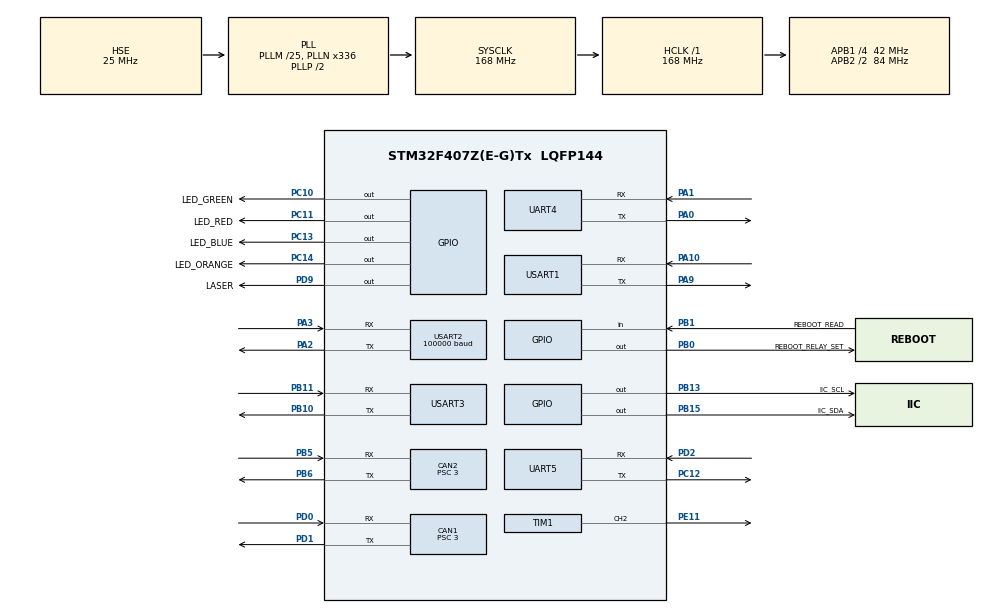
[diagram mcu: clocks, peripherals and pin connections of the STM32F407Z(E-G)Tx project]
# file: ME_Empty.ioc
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CAN1.ABOM=ENABLE
CAN1.AWUM=ENABLE
CAN1.BS1=CAN_BS1_9TQ
CAN1.BS2=CAN_BS2_4TQ
CAN1.CalculateBaudRate=1000000
CAN1.CalculateTimeBit=999.99
CAN1.CalculateTimeQuantum=71.42857142857143
CAN1.NART=ENABLE
CAN1.Prescaler=3
CAN1.TXFP=ENABLE
CAN2.ABOM=ENABLE
CAN2.AWUM=ENABLE
CAN2.BS1=CAN_BS1_9TQ
CAN2.BS2=CAN_BS2_4TQ
CAN2.CalculateBaudRate=1000000
CAN2.CalculateTimeBit=999.99
CAN2.CalculateTimeQuantum=71.42857142857143
CAN2.NART=ENABLE
CAN2.Prescaler=3
CAN2.TXFP=ENABLE
Dma.Request0=UART4_RX
Dma.Request1=UART5_RX
Dma.Request2=UART5_TX
Dma.Request3=USART1_RX
Dma.Request4=USART2_RX
Dma.Request5=USART3_RX
Dma.Request6=USART1_TX
Dma.Request7=UART4_TX
Dma.Request8=USART3_TX
Dma.UART4_RX.0.Direction=DMA_PERIPH_TO_MEMORY
Dma.UART4_RX.0.FIFOMode=DMA_FIFOMODE_DISABLE
Dma.UART4_RX.0.Instance=DMA1_Stream2
Dma.UART4_RX.0.MemDataAlignment=DMA_MDATAALIGN_BYTE
Dma.UART4_RX.0.MemInc=DMA_MINC_ENABLE
Dma.UART4_RX.0.Mode=DMA_CIRCULAR
Dma.UART4_RX.0.PeriphDataAlignment=DMA_PDATAALIGN_BYTE
Dma.UART4_RX.0.PeriphInc=DMA_PINC_DISABLE
Dma.UART4_RX.0.Priority=DMA_PRIORITY_LOW
Dma.UART4_TX.7.Direction=DMA_MEMORY_TO_PERIPH
Dma.UART4_TX.7.FIFOMode=DMA_FIFOMODE_DISABLE
Dma.UART4_TX.7.Instance=DMA1_Stream4
Dma.UART4_TX.7.MemDataAlignment=DMA_MDATAALIGN_BYTE
Dma.UART4_TX.7.MemInc=DMA_MINC_ENABLE
Dma.UART4_TX.7.Mode=DMA_NORMAL
Dma.UART4_TX.7.PeriphDataAlignment=DMA_PDATAALIGN_BYTE
Dma.UART4_TX.7.PeriphInc=DMA_PINC_DISABLE
Dma.UART4_TX.7.Priority=DMA_PRIORITY_LOW
Dma.UART5_RX.1.Direction=DMA_PERIPH_TO_MEMORY
Dma.UART5_RX.1.FIFOMode=DMA_FIFOMODE_DISABLE
Dma.UART5_RX.1.Instance=DMA1_Stream0
Dma.UART5_RX.1.MemDataAlignment=DMA_MDATAALIGN_BYTE
Dma.UART5_RX.1.MemInc=DMA_MINC_ENABLE
Dma.UART5_RX.1.Mode=DMA_CIRCULAR
Dma.UART5_RX.1.PeriphDataAlignment=DMA_PDATAALIGN_BYTE
Dma.UART5_RX.1.PeriphInc=DMA_PINC_DISABLE
Dma.UART5_RX.1.Priority=DMA_PRIORITY_LOW
Dma.UART5_TX.2.Direction=DMA_MEMORY_TO_PERIPH
Dma.UART5_TX.2.FIFOMode=DMA_FIFOMODE_DISABLE
Dma.UART5_TX.2.Instance=DMA1_Stream7
Dma.UART5_TX.2.MemDataAlignment=DMA_MDATAALIGN_BYTE
Dma.UART5_TX.2.MemInc=DMA_MINC_ENABLE
Dma.UART5_TX.2.Mode=DMA_NORMAL
Dma.UART5_TX.2.PeriphDataAlignment=DMA_PDATAALIGN_BYTE
Dma.UART5_TX.2.PeriphInc=DMA_PINC_DISABLE
Dma.UART5_TX.2.Priority=DMA_PRIORITY_LOW
Dma.USART1_RX.3.Direction=DMA_PERIPH_TO_MEMORY
Dma.USART1_RX.3.FIFOMode=DMA_FIFOMODE_DISABLE
Dma.USART1_RX.3.Instance=DMA2_Stream2
Dma.USART1_RX.3.MemDataAlignment=DMA_MDATAALIGN_BYTE
Dma.USART1_RX.3.MemInc=DMA_MINC_ENABLE
Dma.USART1_RX.3.Mode=DMA_CIRCULAR
Dma.USART1_RX.3.PeriphDataAlignment=DMA_PDATAALIGN_BYTE
Dma.USART1_RX.3.PeriphInc=DMA_PINC_DISABLE
Dma.USART1_RX.3.Priority=DMA_PRIORITY_VERY_HIGH
Dma.USART1_TX.6.Direction=DMA_MEMORY_TO_PERIPH
Dma.USART1_TX.6.FIFOMode=DMA_FIFOMODE_DISABLE
Dma.USART1_TX.6.Instance=DMA2_Stream7
Dma.USART1_TX.6.MemDataAlignment=DMA_MDATAALIGN_BYTE
Dma.USART1_TX.6.MemInc=DMA_MINC_ENABLE
Dma.USART1_TX.6.Mode=DMA_NORMAL
Dma.USART1_TX.6.PeriphDataAlignment=DMA_PDATAALIGN_BYTE
Dma.USART1_TX.6.PeriphInc=DMA_PINC_DISABLE
Dma.USART1_TX.6.Priority=DMA_PRIORITY_VERY_HIGH
Dma.USART2_RX.4.Direction=DMA_PERIPH_TO_MEMORY
Dma.USART2_RX.4.FIFOMode=DMA_FIFOMODE_DISABLE
Dma.USART2_RX.4.Instance=DMA1_Stream5
Dma.USART2_RX.4.MemDataAlignment=DMA_MDATAALIGN_BYTE
Dma.USART2_RX.4.MemInc=DMA_MINC_ENABLE
Dma.USART2_RX.4.Mode=DMA_CIRCULAR
Dma.USART2_RX.4.PeriphDataAlignment=DMA_PDATAALIGN_BYTE
Dma.USART2_RX.4.PeriphInc=DMA_PINC_DISABLE
Dma.USART2_RX.4.Priority=DMA_PRIORITY_LOW
Dma.USART3_RX.5.Direction=DMA_PERIPH_TO_MEMORY
Dma.USART3_RX.5.FIFOMode=DMA_FIFOMODE_DISABLE
Dma.USART3_RX.5.Instance=DMA1_Stream1
Dma.USART3_RX.5.MemDataAlignment=DMA_MDATAALIGN_BYTE
Dma.USART3_RX.5.MemInc=DMA_MINC_ENABLE
Dma.USART3_RX.5.Mode=DMA_CIRCULAR
Dma.USART3_RX.5.PeriphDataAlignment=DMA_PDATAALIGN_BYTE
Dma.USART3_RX.5.PeriphInc=DMA_PINC_DISABLE
Dma.USART3_RX.5.Priority=DMA_PRIORITY_HIGH
Dma.USART3_TX.8.Direction=DMA_MEMORY_TO_PERIPH
Dma.USART3_TX.8.FIFOMode=DMA_FIFOMODE_DISABLE
Dma.USART3_TX.8.Instance=DMA1_Stream3
Dma.USART3_TX.8.MemDataAlignment=DMA_MDATAALIGN_BYTE
Dma.USART3_TX.8.MemInc=DMA_MINC_ENABLE
Dma.USART3_TX.8.Mode=DMA_NORMAL
Dma.USART3_TX.8.PeriphDataAlignment=DMA_PDATAALIGN_BYTE
Dma.USART3_TX.8.PeriphInc=DMA_PINC_DISABLE
Dma.USART3_TX.8.Priority=DMA_PRIORITY_HIGH
FREERTOS.Tasks01=defaultTask,0,128,StartDefaultTask,Default,NULL,Dynamic,NULL,NULL;RealtimeTask,2,1024,Realtime_Task,As weak,NULL,Dynamic,NULL,NULL;ControlTask,1,1024,Control_Task,As weak,NULL,Dynamic,NULL,NULL;interactiontask,1,256,Interaction_Task,As weak,NULL,Dynamic,NULL,NULL
Mcu.Family=STM32F4
Mcu.Name=STM32F407Z(E-G)Tx
Mcu.Package=LQFP144
NVIC.CAN1_RX0_IRQn=true\:5\:0\:false\:false\:true\:true\:true\:true
NVIC.CAN2_RX0_IRQn=true\:5\:0\:false\:false\:true\:true\:true\:true
NVIC.DMA1_Stream0_IRQn=true\:5\:0\:false\:false\:true\:true\:false\:true
NVIC.DMA1_Stream1_IRQn=true\:5\:0\:false\:false\:true\:true\:false\:true
NVIC.DMA1_Stream2_IRQn=true\:5\:0\:false\:false\:true\:true\:false\:true
NVIC.DMA1_Stream3_IRQn=true\:5\:0\:false\:false\:true\:true\:false\:true
NVIC.DMA1_Stream4_IRQn=true\:5\:0\:false\:false\:true\:true\:false\:true
NVIC.DMA1_Stream5_IRQn=true\:5\:0\:false\:false\:true\:true\:false\:true
NVIC.DMA1_Stream7_IRQn=true\:5\:0\:false\:false\:true\:true\:false\:true
NVIC.DMA2_Stream2_IRQn=true\:5\:0\:false\:false\:true\:true\:false\:true
NVIC.DMA2_Stream7_IRQn=true\:5\:0\:false\:false\:true\:true\:false\:true
NVIC.PriorityGroup=NVIC_PRIORITYGROUP_4
NVIC.TIM2_IRQn=true\:15\:0\:false\:false\:true\:false\:false\:true
NVIC.TimeBase=TIM2_IRQn
NVIC.TimeBaseIP=TIM2
NVIC.UART4_IRQn=true\:5\:0\:false\:false\:true\:true\:true\:true
NVIC.UART5_IRQn=true\:5\:0\:false\:false\:true\:true\:true\:true
NVIC.USART1_IRQn=true\:5\:0\:false\:false\:true\:true\:true\:true
NVIC.USART2_IRQn=true\:5\:0\:false\:false\:true\:true\:true\:true
NVIC.USART3_IRQn=true\:5\:0\:false\:false\:true\:true\:true\:true
PA0-WKUP.Mode=Asynchronous
PA0-WKUP.Signal=UART4_TX
PA1.Mode=Asynchronous
PA1.Signal=UART4_RX
PA10.Mode=Asynchronous
PA10.Signal=USART1_RX
PA13.Mode=Serial_Wire
PA13.Signal=SYS_JTMS-SWDIO
PA14.Mode=Serial_Wire
PA14.Signal=SYS_JTCK-SWCLK
PA2.Mode=Asynchronous
PA2.Signal=USART2_TX
PA3.Mode=Asynchronous
PA3.Signal=USART2_RX
PA6.Signal=S_TIM3_CH1
PA7.Signal=S_TIM3_CH2
PA9.Mode=Asynchronous
PA9.Signal=USART1_TX
PB0.GPIO_Label=REBOOT_RELAY_SET
PB0.Signal=GPIO_Output
PB1.GPIO_Label=REBOOT_READ
PB1.Signal=GPIO_Input
PB10.Mode=Asynchronous
PB10.Signal=USART3_TX
PB11.Mode=Asynchronous
PB11.Signal=USART3_RX
PB13.GPIO_Label=IIC_SCL
PB13.GPIO_Speed=GPIO_SPEED_FREQ_VERY_HIGH
PB13.PinState=GPIO_PIN_SET
PB13.Signal=GPIO_Output
PB15.GPIO_Label=IIC_SDA
PB15.GPIO_Speed=GPIO_SPEED_FREQ_VERY_HIGH
PB15.PinState=GPIO_PIN_SET
PB15.Signal=GPIO_Output
PB5.Mode=CAN_Activate
PB5.Signal=CAN2_RX
PB6.Mode=CAN_Activate
PB6.Signal=CAN2_TX
PC10.GPIO_Label=LED_GREEN
PC10.Signal=GPIO_Output
PC11.GPIO_Label=LED_RED
PC11.PinState=GPIO_PIN_SET
PC11.Signal=GPIO_Output
PC12.Mode=Asynchronous
PC12.Signal=UART5_TX
PC13-ANTI_TAMP.GPIO_Label=LED_BLUE
PC13-ANTI_TAMP.PinState=GPIO_PIN_SET
PC13-ANTI_TAMP.Signal=GPIO_Output
PC14-OSC32_IN.GPIO_Label=LED_ORANGE
PC14-OSC32_IN.PinState=GPIO_PIN_SET
PC14-OSC32_IN.Signal=GPIO_Output
PC6.Signal=S_TIM8_CH1
PC7.Signal=S_TIM8_CH2
PC8.Signal=S_TIM8_CH3
PC9.Signal=S_TIM8_CH4
PD0.Mode=CAN_Activate
PD0.Signal=CAN1_RX
PD1.Mode=CAN_Activate
PD1.Signal=CAN1_TX
PD12.Signal=S_TIM4_CH1
PD13.Signal=S_TIM4_CH2
PD14.Signal=S_TIM4_CH3
PD15.Signal=S_TIM4_CH4
PD2.Mode=Asynchronous
PD2.Signal=UART5_RX
PD9.GPIO_Label=LASER
PD9.PinState=GPIO_PIN_SET
PD9.Signal=GPIO_Output
PE11.Signal=S_TIM1_CH2
PE9.Signal=S_TIM1_CH1
PH0-OSC_IN.Mode=HSE-External-Oscillator
PH0-OSC_IN.Signal=RCC_OSC_IN
PH1-OSC_OUT.Mode=HSE-External-Oscillator
PH1-OSC_OUT.Signal=RCC_OSC_OUT
ProjectManager.HeapSize=0x200
ProjectManager.StackSize=0x400
ProjectManager.TargetToolchain=MDK-ARM V5.32
RCC.48MHZClocksFreq_Value=84000000
RCC.AHBFreq_Value=168000000
RCC.APB1CLKDivider=RCC_HCLK_DIV4
RCC.APB1Freq_Value=42000000
RCC.APB1TimFreq_Value=84000000
RCC.APB2CLKDivider=RCC_HCLK_DIV2
RCC.APB2Freq_Value=84000000
RCC.APB2TimFreq_Value=168000000
RCC.CortexFreq_Value=168000000
RCC.HCLKFreq_Value=168000000
RCC.HSE_VALUE=25000000
RCC.HSI_VALUE=16000000
RCC.LSE_VALUE=32768
RCC.PLLM=25
RCC.PLLN=336
RCC.PLLSourceVirtual=RCC_PLLSOURCE_HSE
RCC.SYSCLKFreq_VALUE=168000000
RCC.SYSCLKSource=RCC_SYSCLKSOURCE_PLLCLK
RCC.VCOOutputFreq_Value=336000000
SH.S_TIM1_CH1.0=TIM1_CH1
SH.S_TIM1_CH2.0=TIM1_CH2,PWM Generation2 CH2
SH.S_TIM3_CH1.0=TIM3_CH1
SH.S_TIM3_CH2.0=TIM3_CH2
SH.S_TIM4_CH1.0=TIM4_CH1
SH.S_TIM4_CH2.0=TIM4_CH2
SH.S_TIM4_CH3.0=TIM4_CH3
SH.S_TIM4_CH4.0=TIM4_CH4
SH.S_TIM8_CH1.0=TIM8_CH1
SH.S_TIM8_CH2.0=TIM8_CH2
SH.S_TIM8_CH3.0=TIM8_CH3
SH.S_TIM8_CH4.0=TIM8_CH4
TIM1.Channel-PWM\ Generation2\ CH2=TIM_CHANNEL_2
TIM1.Period=1000-1
TIM1.Prescaler=3360-1
UART4.VirtualMode=Asynchronous
UART5.VirtualMode=Asynchronous
USART1.VirtualMode=VM_ASYNC
USART2.BaudRate=100000
USART2.Parity=PARITY_EVEN
USART2.VirtualMode=VM_ASYNC
USART3.VirtualMode=VM_ASYNC
VP_FREERTOS_VS_CMSIS_V1.Mode=CMSIS_V1
VP_SYS_VS_tim2.Mode=TIM2
board=custom

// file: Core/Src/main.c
/* USER CODE BEGIN Header */
/**
  ******************************************************************************
  * @file           : main.c
  * @brief          : Main program body
  ******************************************************************************
  * @attention
  *
  * <h2><center>&copy; Copyright (c) 2021 STMicroelectronics.
  * All rights reserved.</center></h2>
  *
  * This software component is licensed by ST under Ultimate Liberty license
  * SLA0044, the "License"; You may not use this file except in compliance with
  * the License. You may obtain a copy of the License at:
  *                             www.st.com/SLA0044
  *
  ******************************************************************************
  */
/* USER CODE END Header */
#include "main.h"
#include "cmsis_os.h"

/* USER CODE BEGIN Includes */
#include "drive.h"
#include "bmi2_defs.h"
#include "bmi.h"
/* USER CODE END Includes */

CAN_HandleTypeDef hcan1;
CAN_HandleTypeDef hcan2;

TIM_HandleTypeDef htim1;

UART_HandleTypeDef huart4;
UART_HandleTypeDef huart5;
UART_HandleTypeDef huart1;
UART_HandleTypeDef huart2;
UART_HandleTypeDef huart3;
DMA_HandleTypeDef hdma_uart4_rx;
DMA_HandleTypeDef hdma_uart4_tx;
DMA_HandleTypeDef hdma_uart5_rx;
DMA_HandleTypeDef hdma_uart5_tx;
DMA_HandleTypeDef hdma_usart1_rx;
DMA_HandleTypeDef hdma_usart1_tx;
DMA_HandleTypeDef hdma_usart2_rx;
DMA_HandleTypeDef hdma_usart3_rx;
DMA_HandleTypeDef hdma_usart3_tx;

osThreadId defaultTaskHandle;
osThreadId RealtimeTaskHandle;
osThreadId ControlTaskHandle;
osThreadId interactiontaskHandle;

void SystemClock_Config(void);
static void MX_GPIO_Init(void);
static void MX_CAN2_Init(void);
static void MX_DMA_Init(void);
static void MX_CAN1_Init(void);
static void MX_UART4_Init(void);
static void MX_UART5_Init(void);
static void MX_USART1_UART_Init(void);
static void MX_USART2_UART_Init(void);
static void MX_USART3_UART_Init(void);
static void MX_TIM1_Init(void);
void StartDefaultTask(void const * argument);
void Realtime_Task(void const * argument);
void Control_Task(void const * argument);
void Interaction_Task(void const * argument);

int main(void)
{

  /* MCU Configuration--------------------------------------------------------*/

  /* Reset of all peripherals, Initializes the Flash interface and the Systick. */
  HAL_Init();

  /* Configure the system clock */
  SystemClock_Config();

  /* USER CODE BEGIN SysInit */
//	HAL_Delay(500);
//	while(BMI_Init()!=BMI2_OK){}
  /* USER CODE END SysInit */

  /* Initialize all configured peripherals */
  MX_GPIO_Init();
  MX_CAN2_Init();
  MX_DMA_Init();
  MX_CAN1_Init();
  MX_UART4_Init();
  MX_UART5_Init();
  MX_USART1_UART_Init();
  MX_USART2_UART_Init();
  MX_USART3_UART_Init();
  MX_TIM1_Init();
  /* USER CODE BEGIN 2 */
	drive_init();
	module_init();
  /* USER CODE END 2 */

  /* Create the thread(s) */
  /* definition and creation of defaultTask */
  osThreadDef(defaultTask, StartDefaultTask, osPriorityNormal, 0, 128);
  defaultTaskHandle = osThreadCreate(osThread(defaultTask), NULL);

  /* definition and creation of RealtimeTask */
  osThreadDef(RealtimeTask, Realtime_Task, osPriorityHigh, 0, 1024);
  RealtimeTaskHandle = osThreadCreate(osThread(RealtimeTask), NULL);

  /* definition and creation of ControlTask */
  osThreadDef(ControlTask, Control_Task, osPriorityAboveNormal, 0, 1024);
  ControlTaskHandle = osThreadCreate(osThread(ControlTask), NULL);

  /* definition and creation of interactiontask */
  osThreadDef(interactiontask, Interaction_Task, osPriorityAboveNormal, 0, 256);
  interactiontaskHandle = osThreadCreate(osThread(interactiontask), NULL);

  /* Start scheduler */
  osKernelStart();

  /* We should never get here as control is now taken by the scheduler */
  /* Infinite loop */
  while (1)
  {

  }
}

void SystemClock_Config(void)
{
  RCC_OscInitTypeDef RCC_OscInitStruct = {0};
  RCC_ClkInitTypeDef RCC_ClkInitStruct = {0};

  /** Configure the main internal regulator output voltage
  */
  __HAL_RCC_PWR_CLK_ENABLE();
  __HAL_PWR_VOLTAGESCALING_CONFIG(PWR_REGULATOR_VOLTAGE_SCALE1);
  /** Initializes the RCC Oscillators according to the specified parameters
  * in the RCC_OscInitTypeDef structure.
  */
  RCC_OscInitStruct.OscillatorType = RCC_OSCILLATORTYPE_HSE;
  RCC_OscInitStruct.HSEState = RCC_HSE_ON;
  RCC_OscInitStruct.PLL.PLLState = RCC_PLL_ON;
  RCC_OscInitStruct.PLL.PLLSource = RCC_PLLSOURCE_HSE;
  RCC_OscInitStruct.PLL.PLLM = 25;
  RCC_OscInitStruct.PLL.PLLN = 336;
  RCC_OscInitStruct.PLL.PLLP = RCC_PLLP_DIV2;
  RCC_OscInitStruct.PLL.PLLQ = 4;
  if (HAL_RCC_OscConfig(&RCC_OscInitStruct) != HAL_OK)
  {
    Error_Handler();
  }
  /** Initializes the CPU, AHB and APB buses clocks
  */
  RCC_ClkInitStruct.ClockType = RCC_CLOCKTYPE_HCLK|RCC_CLOCKTYPE_SYSCLK
                              |RCC_CLOCKTYPE_PCLK1|RCC_CLOCKTYPE_PCLK2;
  RCC_ClkInitStruct.SYSCLKSource = RCC_SYSCLKSOURCE_PLLCLK;
  RCC_ClkInitStruct.AHBCLKDivider = RCC_SYSCLK_DIV1;
  RCC_ClkInitStruct.APB1CLKDivider = RCC_HCLK_DIV4;
  RCC_ClkInitStruct.APB2CLKDivider = RCC_HCLK_DIV2;

  if (HAL_RCC_ClockConfig(&RCC_ClkInitStruct, FLASH_LATENCY_5) != HAL_OK)
  {
    Error_Handler();
  }
}

static void MX_CAN1_Init(void)
{

  hcan1.Instance = CAN1;
  hcan1.Init.Prescaler = 3;
  hcan1.Init.Mode = CAN_MODE_NORMAL;
  hcan1.Init.SyncJumpWidth = CAN_SJW_1TQ;
  hcan1.Init.TimeSeg1 = CAN_BS1_9TQ;
  hcan1.Init.TimeSeg2 = CAN_BS2_4TQ;
  hcan1.Init.TimeTriggeredMode = DISABLE;
  hcan1.Init.AutoBusOff = ENABLE;
  hcan1.Init.AutoWakeUp = ENABLE;
  hcan1.Init.AutoRetransmission = ENABLE;
  hcan1.Init.ReceiveFifoLocked = DISABLE;
  hcan1.Init.TransmitFifoPriority = ENABLE;
  if (HAL_CAN_Init(&hcan1) != HAL_OK)
  {
    Error_Handler();
  }

}

static void MX_CAN2_Init(void)
{

  hcan2.Instance = CAN2;
  hcan2.Init.Prescaler = 3;
  hcan2.Init.Mode = CAN_MODE_NORMAL;
  hcan2.Init.SyncJumpWidth = CAN_SJW_1TQ;
  hcan2.Init.TimeSeg1 = CAN_BS1_9TQ;
  hcan2.Init.TimeSeg2 = CAN_BS2_4TQ;
  hcan2.Init.TimeTriggeredMode = DISABLE;
  hcan2.Init.AutoBusOff = ENABLE;
  hcan2.Init.AutoWakeUp = ENABLE;
  hcan2.Init.AutoRetransmission = ENABLE;
  hcan2.Init.ReceiveFifoLocked = DISABLE;
  hcan2.Init.TransmitFifoPriority = ENABLE;
  if (HAL_CAN_Init(&hcan2) != HAL_OK)
  {
    Error_Handler();
  }

}

static void MX_TIM1_Init(void)
{

  TIM_MasterConfigTypeDef sMasterConfig = {0};
  TIM_OC_InitTypeDef sConfigOC = {0};
  TIM_BreakDeadTimeConfigTypeDef sBreakDeadTimeConfig = {0};

  htim1.Instance = TIM1;
  htim1.Init.Prescaler = 3360-1;
  htim1.Init.CounterMode = TIM_COUNTERMODE_UP;
  htim1.Init.Period = 1000-1;
  htim1.Init.ClockDivision = TIM_CLOCKDIVISION_DIV1;
  htim1.Init.RepetitionCounter = 0;
  htim1.Init.AutoReloadPreload = TIM_AUTORELOAD_PRELOAD_DISABLE;
  if (HAL_TIM_PWM_Init(&htim1) != HAL_OK)
  {
    Error_Handler();
  }
  sMasterConfig.MasterOutputTrigger = TIM_TRGO_RESET;
  sMasterConfig.MasterSlaveMode = TIM_MASTERSLAVEMODE_DISABLE;
  if (HAL_TIMEx_MasterConfigSynchronization(&htim1, &sMasterConfig) != HAL_OK)
  {
    Error_Handler();
  }
  sConfigOC.OCMode = TIM_OCMODE_PWM1;
  sConfigOC.Pulse = 0;
  sConfigOC.OCPolarity = TIM_OCPOLARITY_HIGH;
  sConfigOC.OCNPolarity = TIM_OCNPOLARITY_HIGH;
  sConfigOC.OCFastMode = TIM_OCFAST_DISABLE;
  sConfigOC.OCIdleState = TIM_OCIDLESTATE_RESET;
  sConfigOC.OCNIdleState = TIM_OCNIDLESTATE_RESET;
  if (HAL_TIM_PWM_ConfigChannel(&htim1, &sConfigOC, TIM_CHANNEL_2) != HAL_OK)
  {
    Error_Handler();
  }
  sBreakDeadTimeConfig.OffStateRunMode = TIM_OSSR_DISABLE;
  sBreakDeadTimeConfig.OffStateIDLEMode = TIM_OSSI_DISABLE;
  sBreakDeadTimeConfig.LockLevel = TIM_LOCKLEVEL_OFF;
  sBreakDeadTimeConfig.DeadTime = 0;
  sBreakDeadTimeConfig.BreakState = TIM_BREAK_DISABLE;
  sBreakDeadTimeConfig.BreakPolarity = TIM_BREAKPOLARITY_HIGH;
  sBreakDeadTimeConfig.AutomaticOutput = TIM_AUTOMATICOUTPUT_DISABLE;
  if (HAL_TIMEx_ConfigBreakDeadTime(&htim1, &sBreakDeadTimeConfig) != HAL_OK)
  {
    Error_Handler();
  }
  HAL_TIM_MspPostInit(&htim1);

}

static void MX_UART4_Init(void)
{

  huart4.Instance = UART4;
  huart4.Init.BaudRate = 115200;
  huart4.Init.WordLength = UART_WORDLENGTH_8B;
  huart4.Init.StopBits = UART_STOPBITS_1;
  huart4.Init.Parity = UART_PARITY_NONE;
  huart4.Init.Mode = UART_MODE_TX_RX;
  huart4.Init.HwFlowCtl = UART_HWCONTROL_NONE;
  huart4.Init.OverSampling = UART_OVERSAMPLING_16;
  if (HAL_UART_Init(&huart4) != HAL_OK)
  {
    Error_Handler();
  }

}

static void MX_UART5_Init(void)
{

  huart5.Instance = UART5;
  huart5.Init.BaudRate = 115200;
  huart5.Init.WordLength = UART_WORDLENGTH_8B;
  huart5.Init.StopBits = UART_STOPBITS_1;
  huart5.Init.Parity = UART_PARITY_NONE;
  huart5.Init.Mode = UART_MODE_TX_RX;
  huart5.Init.HwFlowCtl = UART_HWCONTROL_NONE;
  huart5.Init.OverSampling = UART_OVERSAMPLING_16;
  if (HAL_UART_Init(&huart5) != HAL_OK)
  {
    Error_Handler();
  }

}

static void MX_USART1_UART_Init(void)
{

  huart1.Instance = USART1;
  huart1.Init.BaudRate = 115200;
  huart1.Init.WordLength = UART_WORDLENGTH_8B;
  huart1.Init.StopBits = UART_STOPBITS_1;
  huart1.Init.Parity = UART_PARITY_NONE;
  huart1.Init.Mode = UART_MODE_TX_RX;
  huart1.Init.HwFlowCtl = UART_HWCONTROL_NONE;
  huart1.Init.OverSampling = UART_OVERSAMPLING_16;
  if (HAL_UART_Init(&huart1) != HAL_OK)
  {
    Error_Handler();
  }

}

static void MX_USART2_UART_Init(void)
{

  huart2.Instance = USART2;
  huart2.Init.BaudRate = 100000;
  huart2.Init.WordLength = UART_WORDLENGTH_8B;
  huart2.Init.StopBits = UART_STOPBITS_1;
  huart2.Init.Parity = UART_PARITY_EVEN;
  huart2.Init.Mode = UART_MODE_TX_RX;
  huart2.Init.HwFlowCtl = UART_HWCONTROL_NONE;
  huart2.Init.OverSampling = UART_OVERSAMPLING_16;
  if (HAL_UART_Init(&huart2) != HAL_OK)
  {
    Error_Handler();
  }

}

static void MX_USART3_UART_Init(void)
{

  huart3.Instance = USART3;
  huart3.Init.BaudRate = 115200;
  huart3.Init.WordLength = UART_WORDLENGTH_8B;
  huart3.Init.StopBits = UART_STOPBITS_1;
  huart3.Init.Parity = UART_PARITY_NONE;
  huart3.Init.Mode = UART_MODE_TX_RX;
  huart3.Init.HwFlowCtl = UART_HWCONTROL_NONE;
  huart3.Init.OverSampling = UART_OVERSAMPLING_16;
  if (HAL_UART_Init(&huart3) != HAL_OK)
  {
    Error_Handler();
  }

}

static void MX_DMA_Init(void)
{

  /* DMA controller clock enable */
  __HAL_RCC_DMA1_CLK_ENABLE();
  __HAL_RCC_DMA2_CLK_ENABLE();

  /* DMA interrupt init */
  /* DMA1_Stream0_IRQn interrupt configuration */
  HAL_NVIC_SetPriority(DMA1_Stream0_IRQn, 5, 0);
  HAL_NVIC_EnableIRQ(DMA1_Stream0_IRQn);
  /* DMA1_Stream1_IRQn interrupt configuration */
  HAL_NVIC_SetPriority(DMA1_Stream1_IRQn, 5, 0);
  HAL_NVIC_EnableIRQ(DMA1_Stream1_IRQn);
  /* DMA1_Stream2_IRQn interrupt configuration */
  HAL_NVIC_SetPriority(DMA1_Stream2_IRQn, 5, 0);
  HAL_NVIC_EnableIRQ(DMA1_Stream2_IRQn);
  /* DMA1_Stream3_IRQn interrupt configuration */
  HAL_NVIC_SetPriority(DMA1_Stream3_IRQn, 5, 0);
  HAL_NVIC_EnableIRQ(DMA1_Stream3_IRQn);
  /* DMA1_Stream4_IRQn interrupt configuration */
  HAL_NVIC_SetPriority(DMA1_Stream4_IRQn, 5, 0);
  HAL_NVIC_EnableIRQ(DMA1_Stream4_IRQn);
  /* DMA1_Stream5_IRQn interrupt configuration */
  HAL_NVIC_SetPriority(DMA1_Stream5_IRQn, 5, 0);
  HAL_NVIC_EnableIRQ(DMA1_Stream5_IRQn);
  /* DMA1_Stream7_IRQn interrupt configuration */
  HAL_NVIC_SetPriority(DMA1_Stream7_IRQn, 5, 0);
  HAL_NVIC_EnableIRQ(DMA1_Stream7_IRQn);
  /* DMA2_Stream2_IRQn interrupt configuration */
  HAL_NVIC_SetPriority(DMA2_Stream2_IRQn, 5, 0);
  HAL_NVIC_EnableIRQ(DMA2_Stream2_IRQn);
  /* DMA2_Stream7_IRQn interrupt configuration */
  HAL_NVIC_SetPriority(DMA2_Stream7_IRQn, 5, 0);
  HAL_NVIC_EnableIRQ(DMA2_Stream7_IRQn);

}

static void MX_GPIO_Init(void)
{
  GPIO_InitTypeDef GPIO_InitStruct = {0};

  /* GPIO Ports Clock Enable */
  __HAL_RCC_GPIOC_CLK_ENABLE();
  __HAL_RCC_GPIOH_CLK_ENABLE();
  __HAL_RCC_GPIOA_CLK_ENABLE();
  __HAL_RCC_GPIOB_CLK_ENABLE();
  __HAL_RCC_GPIOE_CLK_ENABLE();
  __HAL_RCC_GPIOD_CLK_ENABLE();

  /*Configure GPIO pin Output Level */
  HAL_GPIO_WritePin(GPIOC, LED_BLUE_Pin|LED_ORANGE_Pin|LED_RED_Pin, GPIO_PIN_SET);

  /*Configure GPIO pin Output Level */
  HAL_GPIO_WritePin(REBOOT_RELAY_SET_GPIO_Port, REBOOT_RELAY_SET_Pin, GPIO_PIN_RESET);

  /*Configure GPIO pin Output Level */
  HAL_GPIO_WritePin(GPIOB, IIC_SCL_Pin|IIC_SDA_Pin, GPIO_PIN_SET);

  /*Configure GPIO pin Output Level */
  HAL_GPIO_WritePin(LASER_GPIO_Port, LASER_Pin, GPIO_PIN_SET);

  /*Configure GPIO pin Output Level */
  HAL_GPIO_WritePin(LED_GREEN_GPIO_Port, LED_GREEN_Pin, GPIO_PIN_RESET);

  /*Configure GPIO pins : LED_BLUE_Pin LED_ORANGE_Pin LED_GREEN_Pin LED_RED_Pin */
  GPIO_InitStruct.Pin = LED_BLUE_Pin|LED_ORANGE_Pin|LED_GREEN_Pin|LED_RED_Pin;
  GPIO_InitStruct.Mode = GPIO_MODE_OUTPUT_PP;
  GPIO_InitStruct.Pull = GPIO_NOPULL;
  GPIO_InitStruct.Speed = GPIO_SPEED_FREQ_LOW;
  HAL_GPIO_Init(GPIOC, &GPIO_InitStruct);

  /*Configure GPIO pins : PA6 PA7 */
  GPIO_InitStruct.Pin = GPIO_PIN_6|GPIO_PIN_7;
  GPIO_InitStruct.Mode = GPIO_MODE_AF_PP;
  GPIO_InitStruct.Pull = GPIO_NOPULL;
  GPIO_InitStruct.Speed = GPIO_SPEED_FREQ_LOW;
  GPIO_InitStruct.Alternate = GPIO_AF2_TIM3;
  HAL_GPIO_Init(GPIOA, &GPIO_InitStruct);

  /*Configure GPIO pin : REBOOT_RELAY_SET_Pin */
  GPIO_InitStruct.Pin = REBOOT_RELAY_SET_Pin;
  GPIO_InitStruct.Mode = GPIO_MODE_OUTPUT_PP;
  GPIO_InitStruct.Pull = GPIO_NOPULL;
  GPIO_InitStruct.Speed = GPIO_SPEED_FREQ_LOW;
  HAL_GPIO_Init(REBOOT_RELAY_SET_GPIO_Port, &GPIO_InitStruct);

  /*Configure GPIO pin : REBOOT_READ_Pin */
  GPIO_InitStruct.Pin = REBOOT_READ_Pin;
  GPIO_InitStruct.Mode = GPIO_MODE_INPUT;
  GPIO_InitStruct.Pull = GPIO_NOPULL;
  HAL_GPIO_Init(REBOOT_READ_GPIO_Port, &GPIO_InitStruct);

  /*Configure GPIO pins : IIC_SCL_Pin IIC_SDA_Pin */
  GPIO_InitStruct.Pin = IIC_SCL_Pin|IIC_SDA_Pin;
  GPIO_InitStruct.Mode = GPIO_MODE_OUTPUT_PP;
  GPIO_InitStruct.Pull = GPIO_NOPULL;
  GPIO_InitStruct.Speed = GPIO_SPEED_FREQ_VERY_HIGH;
  HAL_GPIO_Init(GPIOB, &GPIO_InitStruct);

  /*Configure GPIO pin : LASER_Pin */
  GPIO_InitStruct.Pin = LASER_Pin;
  GPIO_InitStruct.Mode = GPIO_MODE_OUTPUT_PP;
  GPIO_InitStruct.Pull = GPIO_NOPULL;
  GPIO_InitStruct.Speed = GPIO_SPEED_FREQ_LOW;
  HAL_GPIO_Init(LASER_GPIO_Port, &GPIO_InitStruct);

  /*Configure GPIO pins : PD12 PD13 PD14 PD15 */
  GPIO_InitStruct.Pin = GPIO_PIN_12|GPIO_PIN_13|GPIO_PIN_14|GPIO_PIN_15;
  GPIO_InitStruct.Mode = GPIO_MODE_AF_PP;
  GPIO_InitStruct.Pull = GPIO_NOPULL;
  GPIO_InitStruct.Speed = GPIO_SPEED_FREQ_LOW;
  GPIO_InitStruct.Alternate = GPIO_AF2_TIM4;
  HAL_GPIO_Init(GPIOD, &GPIO_InitStruct);

  /*Configure GPIO pins : PC6 PC7 PC8 PC9 */
  GPIO_InitStruct.Pin = GPIO_PIN_6|GPIO_PIN_7|GPIO_PIN_8|GPIO_PIN_9;
  GPIO_InitStruct.Mode = GPIO_MODE_AF_PP;
  GPIO_InitStruct.Pull = GPIO_NOPULL;
  GPIO_InitStruct.Speed = GPIO_SPEED_FREQ_LOW;
  GPIO_InitStruct.Alternate = GPIO_AF3_TIM8;
  HAL_GPIO_Init(GPIOC, &GPIO_InitStruct);

}

void StartDefaultTask(void const * argument)
{
  for(;;)
  {
    osDelay(1);
  }
}

__weak void Realtime_Task(void const * argument)
{
  for(;;)
  {
    osDelay(1);
  }
}

__weak void Control_Task(void const * argument)
{
  for(;;)
  {
    osDelay(1);
  }
}

__weak void Interaction_Task(void const * argument)
{
  for(;;)
  {
    osDelay(1);
  }
}

void HAL_TIM_PeriodElapsedCallback(TIM_HandleTypeDef *htim)
{
  if (htim->Instance == TIM2) {
    HAL_IncTick();
  }
}

void Error_Handler(void)
{
  __disable_irq();
  while (1)
  {
  }
}

/************************ (C) COPYRIGHT STMicroelectronics *****END OF FILE****/
